# psc3m6 register map
Vendor: Infineon Technologies; Series: PSC3M6; File version: 1.0
CPU: CM33 r0p1, little endian, MPU, FPU, DSP, VTOR, 3 interrupt priority bits, 167 interrupts
Registers are 32-bit, read-write, reset 0x0 unless marked. A register's access mark holds for its fields unless they carry their own. Offsets are from the block's base; [hi:lo] are bit positions; lines under a group give offsets from that group; {n}, {i} and the like mark numbered series; <NAME> marks a mode.

## DEBUG600
Base 0x42250000
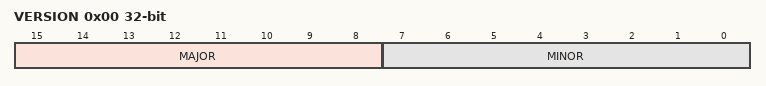
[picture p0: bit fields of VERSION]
0x00 VERSION ro reset not defined — IP Version Information
  [15:8] MAJOR — IP Major Revision Number
  [7:0] MINOR — IP Minor Revision Number

## MXWOUND — 0
Base 0x42280000
0x00 CTL — MXWOUND Control Reg
  [31] ENABLED — IP enable: '0': Disabled. IP SC logic is not clocked (but does not change the state). '1': Enabled. IP SC logic is clocked.
{0x100+0x40*i} MXWOUND_PROP[{i}] (i=0..1) group — 0
  0x00 PROP — Property value register
    [31:0] PROP — Property bit value

## HSIOM — IO Matrix (IOM)
Base 0x42400000
{0x0+0x10*i} PRT[{i}] (i=0..13) group — HSIOM port registers
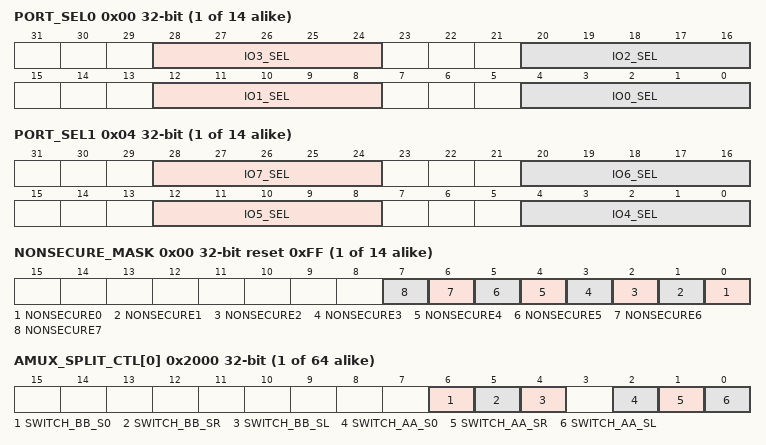
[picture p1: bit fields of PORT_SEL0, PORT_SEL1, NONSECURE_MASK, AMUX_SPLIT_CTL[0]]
  0x00 PORT_SEL0 — Port selection 0
    [28:24] IO3_SEL — Selects connection for IO pin 3 route.
    [20:16] IO2_SEL — Selects connection for IO pin 2 route.
    [12:8] IO1_SEL — Selects connection for IO pin 1 route.
    [4:0] IO0_SEL — Selects connection for IO pin 0 route.
      0=GPIO (GPIO controls 'out'); 1=GPIO_DSI (GPIO controls 'out', DSI controls 'output enable'); 2=DSI_DSI (DSI controls 'out' and 'output enable'); 3=DSI_GPIO (DSI controls 'out', GPIO controls 'output enable'); 4=AMUXA (Analog mux bus A); 5=AMUXB (Analog mux bus B); 6=AMUXA_DSI (Analog mux bus A, DSI control); 7=AMUXB_DSI (Analog mux bus B, DSI control); {v}=ACT_{v-8} (Active functionality {v-8}) (v=8..11); {v}=DS_{v-12} (DeepSleep functionality {v-12}) (v=12..15); {v}=ACT_{v-12} (Active functionality {v-12}) (v=16..27); {v}=DS_{v-24} (DeepSleep functionality {v-24}) (v=28..31)
  0x04 PORT_SEL1 — Port selection 1
    [28:24] IO7_SEL — Selects connection for IO pin 7 route.
    [20:16] IO6_SEL — Selects connection for IO pin 6 route.
    [12:8] IO5_SEL — Selects connection for IO pin 5 route.
    [4:0] IO4_SEL — Selects connection for IO pin 4 route. See PORT_SEL0 for connection details.
{0x1000+0x10*i} SECURE_PRT[{i}] (i=0..13) group — HSIOM secure attribute port registers
  0x00 NONSECURE_MASK reset 0xFF
    [n] NONSECURE{n} (n=0..7) — Non-secure attribute for IO{n}. 0 - Allows Secure access only. 1 - Allows Non-secure access only.
{0x2000+4i} AMUX_SPLIT_CTL[{i}] (i=0..63) — AMUX splitter cell control
  [6] SWITCH_BB_S0 — T-switch control for AMUXBUSB vssa/ground switch.
  [5] SWITCH_BB_SR — T-switch control for Right AMUXBUSB switch.
  [4] SWITCH_BB_SL — T-switch control for Left AMUXBUSB switch.
  [2] SWITCH_AA_S0 — T-switch control for AMUXBUSA vssa/ground switch: '0': switch open. '1': switch closed.
  [1] SWITCH_AA_SR — T-switch control for Right AMUXBUSA switch: '0': switch open. '1': switch closed.
  [0] SWITCH_AA_SL — T-switch control for Left AMUXBUSA switch: '0': switch open. '1': switch closed.
{0x2200+4i} MONITOR_CTL_{i} (i=0..3) — Power/Ground Monitor cell control {i}
  [31:0] MONITOR_EN — control for switch, which connects the power/ground supply to AMUXBUS_A/B respectively when switch is closed: '0': switch open. '1': switch closed.

## CANFD0 (part 3 of 3) — CAN Controller
Base 0x42800000
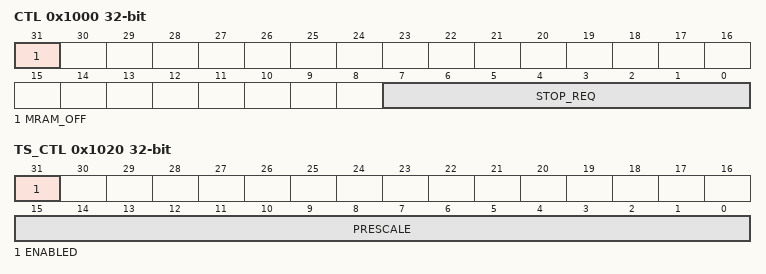
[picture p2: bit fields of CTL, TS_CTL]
0x1000 CTL — Global CAN control register
  [31] MRAM_OFF — MRAM off 0= Default MRAM on (with MRAM retained in DeepSleep). 1= Switch MRAM off (not retained) to save power. Before setting this bit all the CAN channels have to be powered down using the STOP_REQ/ACK bits. When the MRAM is off any access attempt to it is considered an address error (as if MRAM_SIZE=0). After switching the MRAM on again software needs to allow for a certain power up time before MRAM can be used, i.e. before STOP_REQ can be de-asserted. The power up time is equivalent to the system SRAM power up time specified in the CPUSS.RAM_PWR_DELAY_CTL register.
  [7:0] STOP_REQ
0x1004 STATUS ro — Global CAN status register
  [7:0] STOP_ACK — Clock Stop Acknowledge for each TTCAN IP. These bits are directly driven by m_ttcan_clkstop_ack of each TTCAN IP. When this bit is set the corresponding TTCAN IP clocks will be gated off, except HCLK will enabled for each AHB write
0x1010 INTR0_CAUSE ro — Consolidated interrupt0 cause register
  [7:0] INT0 — Show pending m_ttcan_int0 of each channel
0x1014 INTR1_CAUSE ro — Consolidated interrupt1 cause register
  [7:0] INT1 — Show pending m_ttcan_int1 of each channel
0x1020 TS_CTL — Time Stamp control register
  [31] ENABLED — Counter enable bit 0 = Count disabled. Stop counting up and keep the counter value 1 = Count enabled. Start counting up from the current value
  [15:0] PRESCALE — Time Stamp counter prescale value. When enabled divide the Host clock (HCLK) by PRESCALE+1 to create Time Stamp clock ticks.
0x1024 TS_CNT — Time Stamp counter value
  [15:0] VALUE — The counter value of the Time Stamp Counter. When enabled this counter will count Time Stamp clock ticks from the pre-scaler. When written this counter and the pre-scaler will reset to 0 (write data is ignored).

## I3C0 (part 1 of 3) — I3C controller top
Base 0x42C10000
0x400 CTRL — I3C Block Control
  [31] ENABLED — I3C Block Pre-Enable When disabled, all write accesses to the I3C configuration registers are ignored. Enable this prior to starting the configuration of the I3C block. Values: 0x0: Disable the I3C block 0x1: Pre-Enable the I3C block
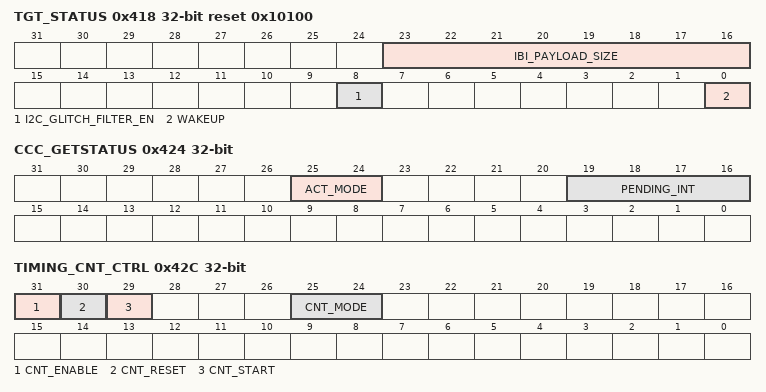
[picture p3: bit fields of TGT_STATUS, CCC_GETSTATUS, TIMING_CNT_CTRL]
0x418 TGT_STATUS ro reset 0x10100 — This register provides additional status information when functioning as a Target.
  [23:16] IBI_PAYLOAD_SIZE
  [8] I2C_GLITCH_FILTER_EN — <HIDDEN>
  [0] WAKEUP
0x424 CCC_GETSTATUS — This register provides additional information on GETSTATUS CCCs received when functioning as a Target.
  [25:24] ACT_MODE, [19:16] PENDING_INT
0x42C TIMING_CNT_CTRL — Controls the Counter used for timestamping I3C-relevant events, especially when communicating with Asynchronous Timing Control Mode 0 enabled.
  [31] CNT_ENABLE, [30] CNT_RESET, [29] CNT_START, [25:24] CNT_MODE wo
0x430 TIMING_CNT0 ro — Most Significant Bits of the Counter
  [31:0] TIMING_COUNTER_MSB
0x434 TIMING_CNT1 ro — Least Significant Bits of the Counter
  [31:0] TIMING_COUNTER_LSB
